# PIC32MM0064GPM028 register map
Vendor: Microchip
Registers are 32-bit, read-write, reset 0x0 unless marked. A register's access mark holds for its fields unless they carry their own. Addresses are absolute, and some are shared; only a register's first bit layout is shown; [hi:lo] are bit positions; {n}, {i} and the like mark numbered series.

## DMAC
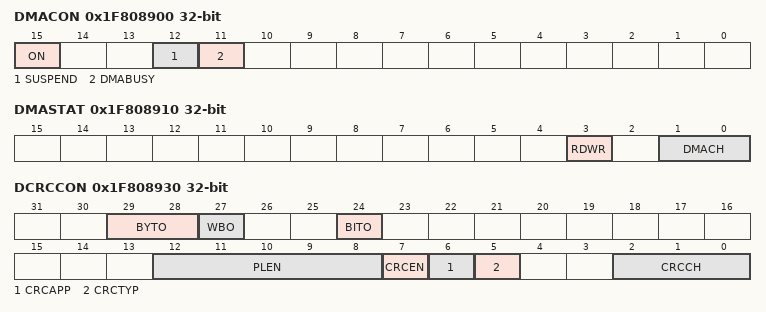
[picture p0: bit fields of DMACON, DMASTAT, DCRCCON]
0x1F808900 DMACON reset not defined — (power-on value ----------------00-0x-----------)
  [15] ON, [12] SUSPEND, [11] DMABUSY
0x1F808910 DMASTAT
  [3] RDWR, [1:0] DMACH
0x1F808920 DMAADDR ro
0x1F808930 DCRCCON reset not defined — (power-on value --xxx--x-----------xxxxx00x--000)
  [29:28] BYTO, [27] WBO, [24] BITO, [12:8] PLEN, [7] CRCEN, [6] CRCAPP, [5] CRCTYP, [2:0] CRCCH
0x1F808940 DCRCDATA
0x1F808950 DCRCXOR

## DMAC0
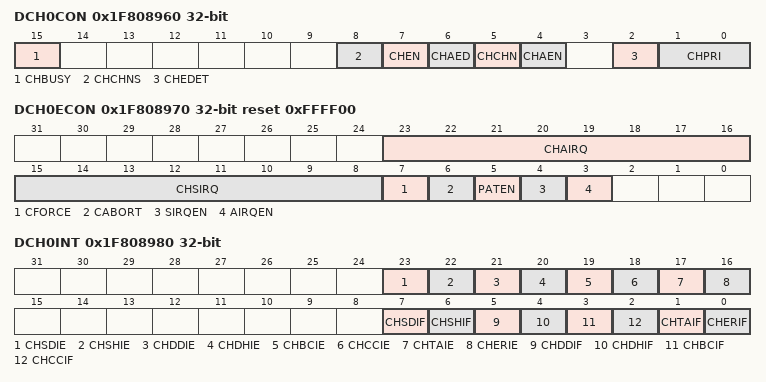
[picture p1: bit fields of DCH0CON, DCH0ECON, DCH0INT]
0x1F808960 DCH0CON reset not defined — (power-on value ----------------x------00000-000)
  [15] CHBUSY, [8] CHCHNS, [7] CHEN, [6] CHAED, [5] CHCHN, [4] CHAEN, [2] CHEDET ro, [1:0] CHPRI
0x1F808970 DCH0ECON reset 0xFFFF00
  [23:16] CHAIRQ
  [15:8] CHSIRQ
  [7] CFORCE — (can only be set)
  [6] CABORT — (can only be set)
  [5] PATEN
  [4] SIRQEN
  [3] AIRQEN
0x1F808980 DCH0INT
  [23] CHSDIE, [22] CHSHIE, [21] CHDDIE, [20] CHDHIE, [19] CHBCIE, [18] CHCCIE, [17] CHTAIE, [16] CHERIE, [7] CHSDIF, [6] CHSHIF, [5] CHDDIF, [4] CHDHIF, [3] CHBCIF, [2] CHCCIF, [1] CHTAIF, [0] CHERIF
0x1F808990 DCH0SSA reset not defined — (power-on value xxxxxxxxxxxxxxxxxxxxxxxxxxxxxxxx)
0x1F8089A0 DCH0DSA reset not defined — (power-on value xxxxxxxxxxxxxxxxxxxxxxxxxxxxxxxx)
0x1F8089B0 DCH0SSIZ reset not defined — (power-on value ----------------xxxxxxxxxxxxxxxx)
  [15:0] CHSSIZ
0x1F8089C0 DCH0DSIZ reset not defined — (power-on value ----------------xxxxxxxxxxxxxxxx)
  [15:0] CHDSIZ
0x1F8089D0 DCH0SPTR reset not defined — (power-on value ----------------xxxxxxxxxxxxxxxx)
  [15:0] CHSPTR
0x1F8089E0 DCH0DPTR ro
  [15:0] CHDPTR
0x1F8089F0 DCH0CSIZ reset not defined — (power-on value ----------------xxxxxxxxxxxxxxxx)
  [15:0] CHCSIZ
0x1F808A00 DCH0CPTR reset not defined — (power-on value ----------------xxxxxxxxxxxxxxxx)
  [15:0] CHCPTR
0x1F808A10 DCH0DAT reset not defined — (power-on value ------------------------xxxxxxxx)
  [7:0] DCHPDAT

## DMAC1
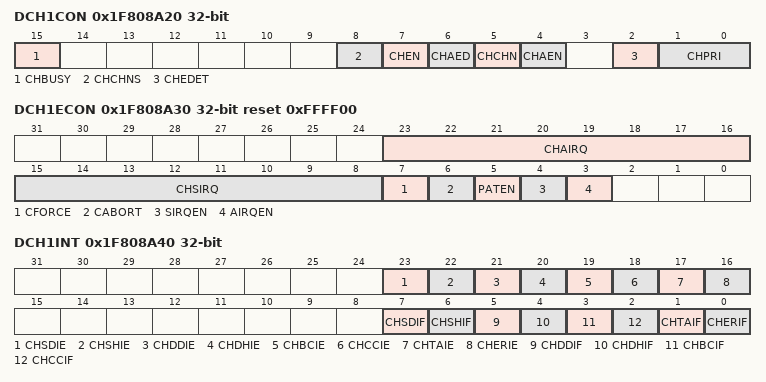
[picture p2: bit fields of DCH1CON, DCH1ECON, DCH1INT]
0x1F808A20 DCH1CON reset not defined — (power-on value ----------------x------00000-000)
  [15] CHBUSY, [8] CHCHNS, [7] CHEN, [6] CHAED, [5] CHCHN, [4] CHAEN, [2] CHEDET ro, [1:0] CHPRI
0x1F808A30 DCH1ECON reset 0xFFFF00
  [23:16] CHAIRQ
  [15:8] CHSIRQ
  [7] CFORCE — (can only be set)
  [6] CABORT — (can only be set)
  [5] PATEN
  [4] SIRQEN
  [3] AIRQEN
0x1F808A40 DCH1INT
  [23] CHSDIE, [22] CHSHIE, [21] CHDDIE, [20] CHDHIE, [19] CHBCIE, [18] CHCCIE, [17] CHTAIE, [16] CHERIE, [7] CHSDIF, [6] CHSHIF, [5] CHDDIF, [4] CHDHIF, [3] CHBCIF, [2] CHCCIF, [1] CHTAIF, [0] CHERIF
0x1F808A50 DCH1SSA reset not defined — (power-on value xxxxxxxxxxxxxxxxxxxxxxxxxxxxxxxx)
0x1F808A60 DCH1DSA reset not defined — (power-on value xxxxxxxxxxxxxxxxxxxxxxxxxxxxxxxx)
0x1F808A70 DCH1SSIZ reset not defined — (power-on value ----------------xxxxxxxxxxxxxxxx)
  [15:0] CHSSIZ
0x1F808A80 DCH1DSIZ reset not defined — (power-on value ----------------xxxxxxxxxxxxxxxx)
  [15:0] CHDSIZ
0x1F808A90 DCH1SPTR reset not defined — (power-on value ----------------xxxxxxxxxxxxxxxx)
  [15:0] CHSPTR
0x1F808AA0 DCH1DPTR ro
  [15:0] CHDPTR
0x1F808AB0 DCH1CSIZ reset not defined — (power-on value ----------------xxxxxxxxxxxxxxxx)
  [15:0] CHCSIZ
0x1F808AC0 DCH1CPTR reset not defined — (power-on value ----------------xxxxxxxxxxxxxxxx)
  [15:0] CHCPTR
0x1F808AD0 DCH1DAT reset not defined — (power-on value ------------------------xxxxxxxx)
  [7:0] DCHPDAT

## DMAC2
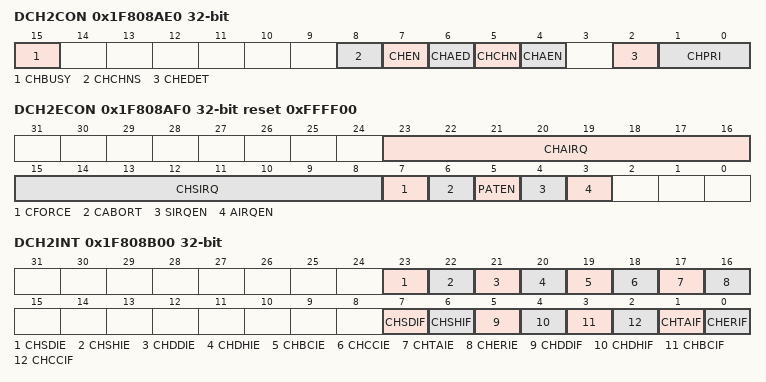
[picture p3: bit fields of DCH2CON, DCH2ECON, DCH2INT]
0x1F808AE0 DCH2CON reset not defined — (power-on value ----------------x------00000-000)
  [15] CHBUSY, [8] CHCHNS, [7] CHEN, [6] CHAED, [5] CHCHN, [4] CHAEN, [2] CHEDET ro, [1:0] CHPRI
0x1F808AF0 DCH2ECON reset 0xFFFF00
  [23:16] CHAIRQ
  [15:8] CHSIRQ
  [7] CFORCE — (can only be set)
  [6] CABORT — (can only be set)
  [5] PATEN
  [4] SIRQEN
  [3] AIRQEN
0x1F808B00 DCH2INT
  [23] CHSDIE, [22] CHSHIE, [21] CHDDIE, [20] CHDHIE, [19] CHBCIE, [18] CHCCIE, [17] CHTAIE, [16] CHERIE, [7] CHSDIF, [6] CHSHIF, [5] CHDDIF, [4] CHDHIF, [3] CHBCIF, [2] CHCCIF, [1] CHTAIF, [0] CHERIF
0x1F808B10 DCH2SSA reset not defined — (power-on value xxxxxxxxxxxxxxxxxxxxxxxxxxxxxxxx)
0x1F808B20 DCH2DSA reset not defined — (power-on value xxxxxxxxxxxxxxxxxxxxxxxxxxxxxxxx)
0x1F808B30 DCH2SSIZ reset not defined — (power-on value ----------------xxxxxxxxxxxxxxxx)
  [15:0] CHSSIZ
0x1F808B40 DCH2DSIZ reset not defined — (power-on value ----------------xxxxxxxxxxxxxxxx)
  [15:0] CHDSIZ
0x1F808B50 DCH2SPTR reset not defined — (power-on value ----------------xxxxxxxxxxxxxxxx)
  [15:0] CHSPTR
0x1F808B60 DCH2DPTR ro
  [15:0] CHDPTR
0x1F808B70 DCH2CSIZ reset not defined — (power-on value ----------------xxxxxxxxxxxxxxxx)
  [15:0] CHCSIZ
0x1F808B80 DCH2CPTR reset not defined — (power-on value ----------------xxxxxxxxxxxxxxxx)
  [15:0] CHCPTR
0x1F808B90 DCH2DAT reset not defined — (power-on value ------------------------xxxxxxxx)
  [7:0] DCHPDAT

## DMAC3
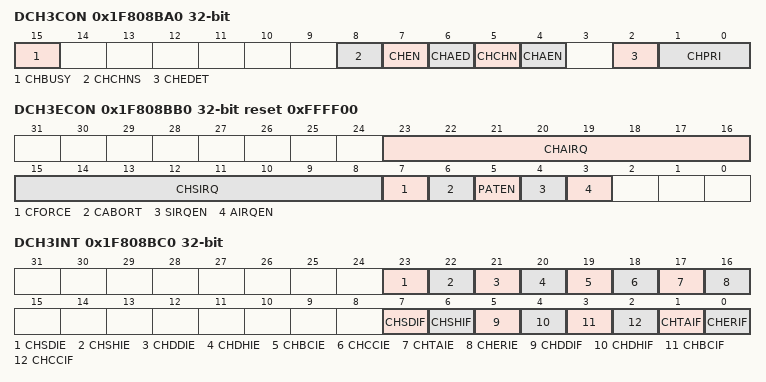
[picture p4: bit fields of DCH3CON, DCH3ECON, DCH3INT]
0x1F808BA0 DCH3CON reset not defined — (power-on value ----------------x------00000-000)
  [15] CHBUSY, [8] CHCHNS, [7] CHEN, [6] CHAED, [5] CHCHN, [4] CHAEN, [2] CHEDET ro, [1:0] CHPRI
0x1F808BB0 DCH3ECON reset 0xFFFF00
  [23:16] CHAIRQ
  [15:8] CHSIRQ
  [7] CFORCE — (can only be set)
  [6] CABORT — (can only be set)
  [5] PATEN
  [4] SIRQEN
  [3] AIRQEN
0x1F808BC0 DCH3INT
  [23] CHSDIE, [22] CHSHIE, [21] CHDDIE, [20] CHDHIE, [19] CHBCIE, [18] CHCCIE, [17] CHTAIE, [16] CHERIE, [7] CHSDIF, [6] CHSHIF, [5] CHDDIF, [4] CHDHIF, [3] CHBCIF, [2] CHCCIF, [1] CHTAIF, [0] CHERIF
0x1F808BD0 DCH3SSA reset not defined — (power-on value xxxxxxxxxxxxxxxxxxxxxxxxxxxxxxxx)
0x1F808BE0 DCH3DSA reset not defined — (power-on value xxxxxxxxxxxxxxxxxxxxxxxxxxxxxxxx)
0x1F808BF0 DCH3SSIZ reset not defined — (power-on value ----------------xxxxxxxxxxxxxxxx)
  [15:0] CHSSIZ
0x1F808C00 DCH3DSIZ reset not defined — (power-on value ----------------xxxxxxxxxxxxxxxx)
  [15:0] CHDSIZ
0x1F808C10 DCH3SPTR reset not defined — (power-on value ----------------xxxxxxxxxxxxxxxx)
  [15:0] CHSPTR
0x1F808C20 DCH3DPTR ro
  [15:0] CHDPTR
0x1F808C30 DCH3CSIZ reset not defined — (power-on value ----------------xxxxxxxxxxxxxxxx)
  [15:0] CHCSIZ
0x1F808C40 DCH3CPTR reset not defined — (power-on value ----------------xxxxxxxxxxxxxxxx)
  [15:0] CHCPTR
0x1F808C50 DCH3DAT reset not defined — (power-on value ------------------------xxxxxxxx)
  [7:0] DCHPDAT

## SABE_UDID
{0x1FC4183C+4i} UDID{i} ro reset not defined (i=1..5)
